AUTOSAR XML (schema 00051)
package /Components
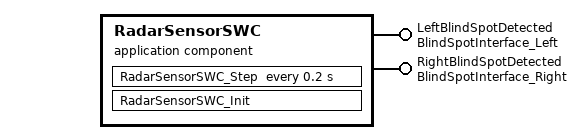
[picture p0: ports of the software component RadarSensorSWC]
  application sw component type RadarSensorSWC
    provide port LeftBlindSpotDetected: nonqueued-sender-com-spec{data-element=detected, init-value=0}, provided-interface=BlindSpotInterface_Left
    provide port RightBlindSpotDetected: nonqueued-sender-com-spec{data-element=detected, init-value=0}, provided-interface=BlindSpotInterface_Right
    behavior RadarSensorSWC_IB: handle-termination-and-restart=NO-SUPPORT
      timing event Event_RadarSensorSWC_Step: start-on-event=RadarSensorSWC_Step, period=0.2
      runnable RadarSensorSWC_Init
      runnable RadarSensorSWC_Step
        data-send-points:
          access OUT_LeftBlindSpotDetected_detected: accessed-variable=LeftBlindSpotDetected.detected
          access OUT_RightBlindSpotDetected_detected: accessed-variable=RightBlindSpotDetected.detected
